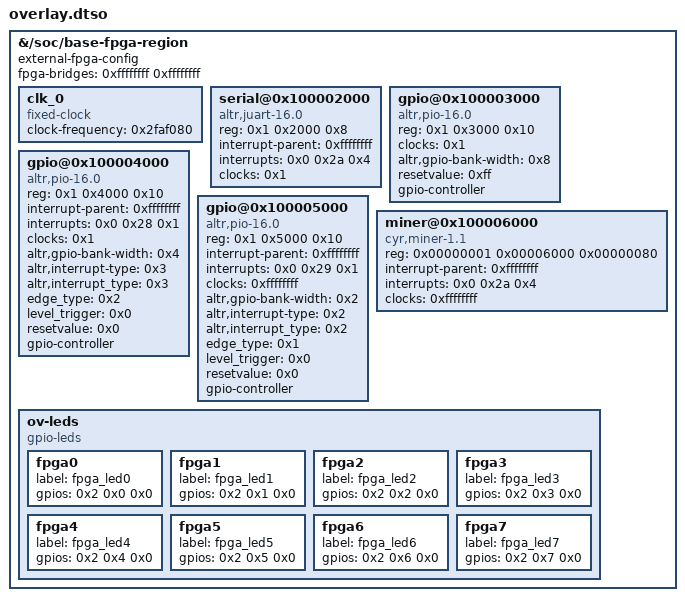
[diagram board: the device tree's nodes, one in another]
/dts-v1/;

/ {

	fragment@0 {
		target-path = "/soc/base-fpga-region";
		#address-cells = <0x1>;
		#size-cells = <0x1>;

		__overlay__ {
			#address-cells = <0x2>;
			#size-cells = <0x1>;
			external-fpga-config;
			fpga-bridges = <0xffffffff 0xffffffff>;
			ranges = <0x0 0x0 0xc0000000 0x20000000 0x1 0x0 0xff200000 0x200000>;

			clk_0 {
				compatible = "fixed-clock";
				#clock-cells = <0x0>;
				clock-frequency = <0x2faf080>;
				linux,phandle = <0x1>;
				phandle = <0x1>;
			};

			serial@0x100002000 {
				compatible = "altr,juart-16.0", "altr,juart-1.0";
				reg = <0x1 0x2000 0x8>;
				interrupt-parent = <0xffffffff>;
				interrupts = <0x0 0x2a 0x4>;
				clocks = <0x1>;
				linux,phandle = <0x3>;
				phandle = <0x3>;
			};

			gpio@0x100003000 {
				compatible = "altr,pio-16.0", "altr,pio-1.0";
				reg = <0x1 0x3000 0x10>;
				clocks = <0x1>;
				altr,gpio-bank-width = <0x8>;
				resetvalue = <0xff>;
				#gpio-cells = <0x2>;
				gpio-controller;
				linux,phandle = <0x2>;
				phandle = <0x2>;
			};

			gpio@0x100004000 {
				compatible = "altr,pio-16.0", "altr,pio-1.0";
				reg = <0x1 0x4000 0x10>;
				interrupt-parent = <0xffffffff>;
				interrupts = <0x0 0x28 0x1>;
				clocks = <0x1>;
				altr,gpio-bank-width = <0x4>;
				altr,interrupt-type = <0x3>;
				altr,interrupt_type = <0x3>;
				edge_type = <0x2>;
				level_trigger = <0x0>;
				resetvalue = <0x0>;
				#gpio-cells = <0x2>;
				gpio-controller;
				linux,phandle = <0x7>;
				phandle = <0x7>;
			};

			gpio@0x100005000 {
				compatible = "altr,pio-16.0", "altr,pio-1.0";
				reg = <0x1 0x5000 0x10>;
				interrupt-parent = <0xffffffff>;
				interrupts = <0x0 0x29 0x1>;
				clocks = <0xffffffff>;
				altr,gpio-bank-width = <0x2>;
				altr,interrupt-type = <0x2>;
				altr,interrupt_type = <0x2>;
				edge_type = <0x1>;
				level_trigger = <0x0>;
				resetvalue = <0x0>;
				#gpio-cells = <0x2>;
				gpio-controller;
				linux,phandle = <0x8>;
				phandle = <0x8>;
			};

                        miner@0x100006000 {
                                compatible = "cyr,miner-1.1", "dev,miner";
                                reg = <0x00000001 0x00006000 0x00000080>;
                                interrupt-parent = <0xffffffff>;
                                interrupts = <0x0 0x2a 0x4>;
                                clocks = <0xffffffff>;
			//	linux,phandle = <0x9>;
			//	phandle = <0x9>;
                        };

			ov-leds {
				compatible = "gpio-leds";

				fpga0 {
					label = "fpga_led0";
					gpios = <0x2 0x0 0x0>;
				};

				fpga1 {
					label = "fpga_led1";
					gpios = <0x2 0x1 0x0>;
				};

				fpga2 {
					label = "fpga_led2";
					gpios = <0x2 0x2 0x0>;
				};

				fpga3 {
					label = "fpga_led3";
					gpios = <0x2 0x3 0x0>;
				};

				fpga4 {
					label = "fpga_led4";
					gpios = <0x2 0x4 0x0>;
				};

				fpga5 {
					label = "fpga_led5";
					gpios = <0x2 0x5 0x0>;
				};

				fpga6 {
					label = "fpga_led6";
					gpios = <0x2 0x6 0x0>;
				};

				fpga7 {
					label = "fpga_led7";
					gpios = <0x2 0x7 0x0>;
				};
			};
		};
	};

	__symbols__ {
		clk_0 = "/fragment@0/__overlay__/clk_0";
		jtag_uart = "/fragment@0/__overlay__/serial@0x100002000";
		led_pio = "/fragment@0/__overlay__/gpio@0x100003000";
		dipsw_pio = "/fragment@0/__overlay__/gpio@0x100004000";
		button_pio = "/fragment@0/__overlay__/gpio@0x100005000";
		miner_0 = "/fragment@0/__overlay__/miner@0x100006000";
	};

	__fixups__ {
		fpga_bridge0 = "/fragment@0/__overlay__:fpga-bridges:0";
		fpga_bridge1 = "/fragment@0/__overlay__:fpga-bridges:4";
		intc = "/fragment@0/__overlay__/serial@0x100002000:interrupt-parent:0", "/fragment@0/__overlay__/gpio@0x100004000:interrupt-parent:0", "/fragment@0/__overlay__/gpio@0x100005000:interrupt-parent:0", "/fragment@0/__overlay__/miner@0x100006000:interrupt-parent:0";
		osc1 = "/fragment@0/__overlay__/gpio@0x100005000:clocks:0";
	};

	__local_fixups__ {

		fragment@0 {

			__overlay__ {

				serial@0x100002000 {
					clocks = <0x0>;
				};

				gpio@0x100003000 {
					clocks = <0x0>;
				};

				gpio@0x100004000 {
					clocks = <0x0>;
				};

				miner@0x100006000 {
					clocks = <0x0>;
				};

				ov-leds {

					fpga0 {
						gpios = <0x0>;
					};

					fpga1 {
						gpios = <0x0>;
					};

					fpga2 {
						gpios = <0x0>;
					};

					fpga3 {
						gpios = <0x0>;
					};

					fpga4 {
						gpios = <0x0>;
					};

					fpga5 {
						gpios = <0x0>;
					};

					fpga6 {
						gpios = <0x0>;
					};

					fpga7 {
						gpios = <0x0>;
					};
				};
			};
		};
	};
};
